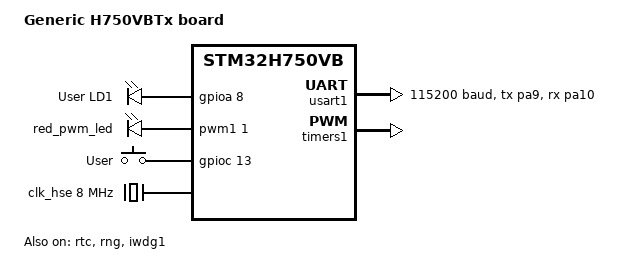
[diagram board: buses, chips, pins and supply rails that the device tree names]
/*
 * Copyright (c) 2020 Teslabs Engineering S.L.
 *
 * SPDX-License-Identifier: Apache-2.0
 */

/dts-v1/;
#include <st/h7/stm32h750Xb.dtsi>
#include <st/h7/stm32h750vbtx-pinctrl.dtsi>
/* #include "arduino_r3_connector.dtsi" */

/ {
	model = "Generic H750VBTx board";
	compatible = "st,stm32h750vb-nucleo";

	chosen {
		zephyr,console = &usart1;
		zephyr,shell-uart = &usart1;
		zephyr,sram = &sram0;
		zephyr,flash = &flash0;
		zephyr,dtcm = &dtcm;
		zephyr,code-partition = &slot0_partition;
	};

	leds {
		compatible = "gpio-leds";
		green_led: led_0 {
			gpios = <&gpioa 8 GPIO_ACTIVE_HIGH>;
			label = "User LD1";
		};
	};

	pwmleds {
		compatible = "pwm-leds";

		red_pwm_led: red_pwm_led {
			pwms = <&pwm1 1 4 PWM_POLARITY_NORMAL>;
		};
	};

	gpio_keys {
		compatible = "gpio-keys";
		user_button: button_0 {
			label = "User";
			gpios = <&gpioc 13 GPIO_ACTIVE_HIGH>;
		};
	};

	aliases {
		led0 = &green_led;
		pwm-led0 = &red_pwm_led;
		sw0 = &user_button;
	};
};

&clk_hse {
	clock-frequency = <DT_FREQ_M(8)>; /* STLink 8MHz clock */
	status = "okay";
};

&pll {
	div-m = <4>;
	mul-n = <400>;
	div-p = <2>;
	div-q = <20>;
	div-r = <2>;
	clocks = <&clk_hse>;
	status = "okay";
};

&rcc {
	clocks = <&pll>;
	clock-frequency = <DT_FREQ_M(400)>;
	d1cpre = <1>;
	hpre = <2>;
	d1ppre = <2>;
	d2ppre1 = <2>;
	d2ppre2 = <2>;
	d3ppre = <2>;
};

&usart1 {
	pinctrl-0 = <&usart1_tx_pa9 &usart1_rx_pa10>;
	current-speed = <115200>;
	status = "okay";
};

&rtc {
	status = "okay";
};

&timers1 {
	status = "okay";

	pwm1: pwm {
		status = "okay";
		pinctrl-0 = <&tim1_ch1_pa8>;
	};
};

&rng {
	status = "okay";
};

&backup_sram {
	status = "okay";
};

&flash0 {
	partitions {
		compatible = "fixed-partitions";
		#address-cells = <1>;
		#size-cells = <1>;

		/* 128KB for bootloader */
		slot0_partition: partition@0 {
			label = "image-0";
			reg = <0x00000000 0x00020000>;
			read-only;
		};
	};
};

&iwdg1 {
	status = "okay";
};
